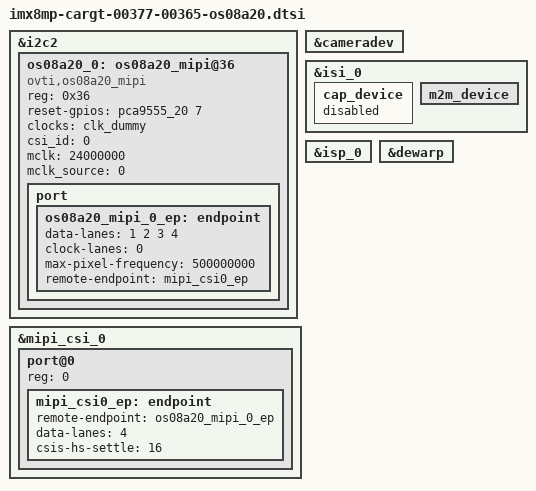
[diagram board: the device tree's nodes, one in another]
/ {
	/* Placeholder camera node for board-specific OS08A20 bring-up. */
};

&i2c2 {
	os08a20_0: os08a20_mipi@36 {
		compatible = "ovti,os08a20_mipi";
		reg = <0x36>;
		reset-gpios = <&pca9555_20 7 GPIO_ACTIVE_HIGH>;
		clocks = <&clk_dummy>;
		clock-names = "csi_mclk";
		csi_id = <0>;
		mclk = <24000000>;
		mclk_source = <0>;
		status = "okay";

		port {
			os08a20_mipi_0_ep: endpoint {
				data-lanes = <1 2 3 4>;
				clock-lanes = <0>;
				max-pixel-frequency = /bits/ 64 <500000000>;
				remote-endpoint = <&mipi_csi0_ep>;
			};
		};
	};
};

&cameradev {
	status = "okay";
};

&isi_0 {
	status = "okay";

	cap_device {
		status = "disabled";
	};

	m2m_device {
		status = "okay";
	};
};

&isp_0 {
	status = "okay";
};

&dewarp {
	status = "okay";
};

&mipi_csi_0 {
	#address-cells = <1>;
	#size-cells = <0>;
	status = "okay";

	port@0 {
		reg = <0>;
		mipi_csi0_ep: endpoint {
			remote-endpoint = <&os08a20_mipi_0_ep>;
			data-lanes = <4>;
			csis-hs-settle = <16>;
		};
	};
};
